# MDR32F8 register map
Vendor: Milandr; File version: 1.0
CPU: CM4 r1p1, little endian, no MPU, no FPU, 3 interrupt priority bits
Registers are 32-bit, read-write, reset 0x0 unless marked. A register's access mark holds for its fields unless they carry their own. Offsets are from the block's base; [hi:lo] are bit positions; {n}, {i} and the like mark numbered series; 'fields as' and 'values as' point back to an identical list.

## ARINC429T — ARINC429 Transive Controller
Base 0x400A0000
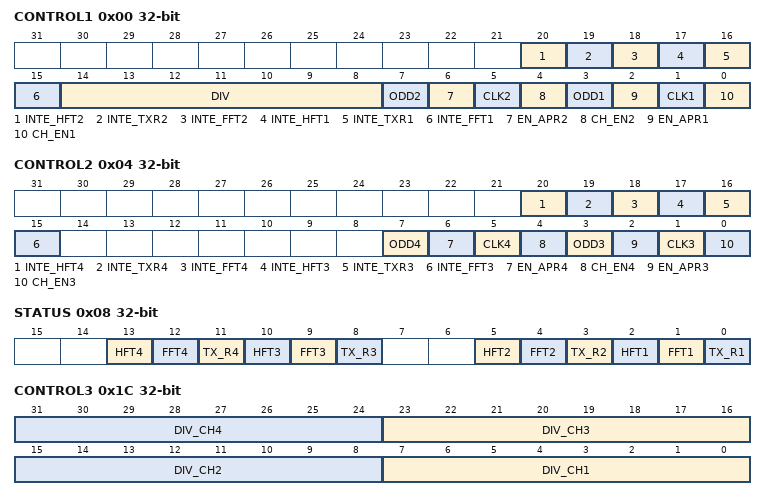
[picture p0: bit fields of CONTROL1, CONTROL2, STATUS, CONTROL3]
0x00 CONTROL1
  [20] INTE_HFT2, [19] INTE_TXR2, [18] INTE_FFT2, [17] INTE_HFT1, [16] INTE_TXR1, [15] INTE_FFT1, [14:8] DIV, [7] ODD2, [6] EN_APR2, [5] CLK2, [4] CH_EN2, [3] ODD1, [2] EN_APR1, [1] CLK1, [0] CH_EN1
0x04 CONTROL2
  [20] INTE_HFT4, [19] INTE_TXR4, [18] INTE_FFT4, [17] INTE_HFT3, [16] INTE_TXR3, [15] INTE_FFT3, [7] ODD4, [6] EN_APR4, [5] CLK4, [4] CH_EN4, [3] ODD3, [2] EN_APR3, [1] CLK3, [0] CH_EN3
0x08 STATUS
  [13] HFT4, [12] FFT4, [11] TX_R4, [10] HFT3, [9] FFT3, [8] TX_R3, [5] HFT2, [4] FFT2, [3] TX_R2, [2] HFT1, [1] FFT1, [0] TX_R1
{0x8+4i} DATA{i}_T wo (i=1..4)
0x1C CONTROL3
  [8n-1:8n-8] DIV_CH{n} (n=1..4)
0x20 CONTROL4
  [3:0] ENSYNC

## MDR_MILDAT_15530 — MIL_DATA
Base 0x400A6000
Same registers: MDR_MILDAT_15531 0x400A8000

## MDR_MIL_STD_15530 — MIL_STD_1553 interfase controller registers
Base 0x400A7000
Same registers: MDR_MIL_STD_15531 0x400A9000
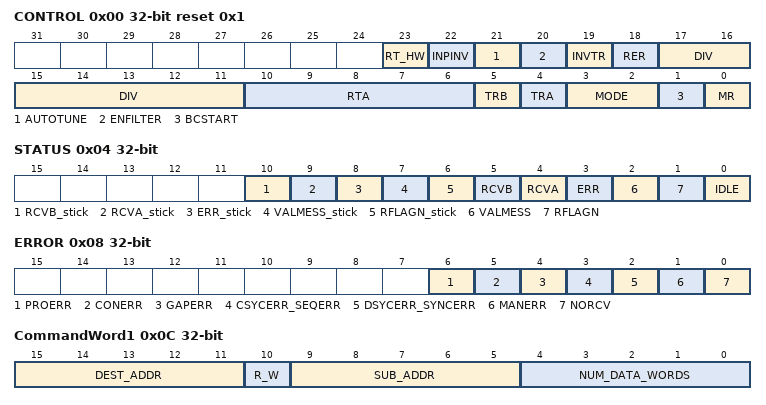
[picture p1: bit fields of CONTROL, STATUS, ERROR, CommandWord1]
0x00 CONTROL reset 0x1 — MIL_STD_1553 Register control
  [23] RT_HW, [22] INPINV, [21] AUTOTUNE, [20] ENFILTER, [19] INVTR, [18] RER, [17:11] DIV, [10:6] RTA, [5] TRB, [4] TRA, [3:2] MODE, [1] BCSTART, [0] MR
0x04 STATUS ro — MIL_STD_1553 Register status
  [10] RCVB_stick, [9] RCVA_stick, [8] ERR_stick, [7] VALMESS_stick, [6] RFLAGN_stick, [5] RCVB, [4] RCVA, [3] ERR, [2] VALMESS, [1] RFLAGN, [0] IDLE
0x08 ERROR ro — MIL_STD_1553 Register error
  [6] PROERR, [5] CONERR, [4] GAPERR, [3] CSYCERR_SEQERR, [2] DSYCERR_SYNCERR, [1] MANERR, [0] NORCV
0x0C CommandWord1 — MIL_STD_1553 Register Command Word 1
  [15:11] DEST_ADDR, [10] R_W, [9:5] SUB_ADDR, [4:0] NUM_DATA_WORDS
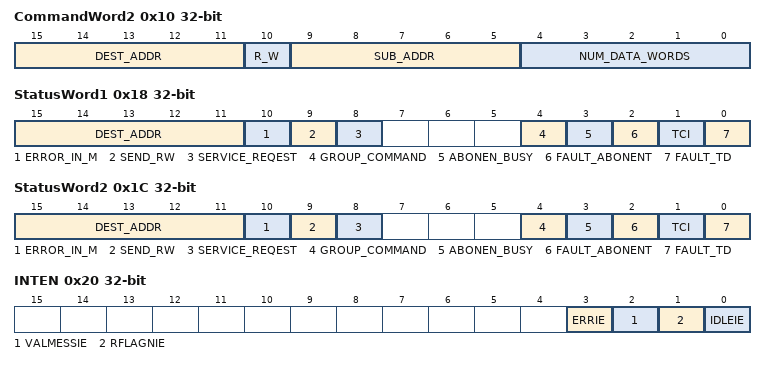
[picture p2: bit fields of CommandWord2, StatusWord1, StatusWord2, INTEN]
0x10 CommandWord2 — MIL_STD_1553 Register Command Word 2
  [15:11] DEST_ADDR, [10] R_W, [9:5] SUB_ADDR, [4:0] NUM_DATA_WORDS
0x14 MODE_DATA — MIL_STD_1553 Register Mode Data
  [15:0] MODE_DATA
0x18 StatusWord1 — MIL_STD_1553 Register Status Word 1
  [15:11] DEST_ADDR, [10] ERROR_IN_M, [9] SEND_RW, [8] SERVICE_REQEST, [4] GROUP_COMMAND, [3] ABONEN_BUSY, [2] FAULT_ABONENT, [1] TCI, [0] FAULT_TD
0x1C StatusWord2 — MIL_STD_1553 Register Status Word 2
  fields as StatusWord1
0x20 INTEN — MIL_STD_1553
  [3] ERRIE, [2] VALMESSIE, [1] RFLAGNIE, [0] IDLEIE
0x24 MSG ro — MIL_STD_1553
  [13:0] MESSAGE_CODE

## ADC0 — ADC
Base 0x400AA000
Same registers: ADC1 0x400AB000
0x00 KEY — Key lock Register
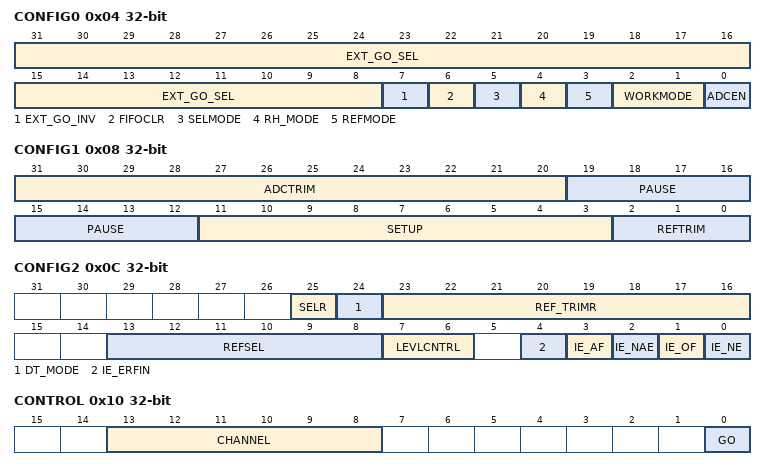
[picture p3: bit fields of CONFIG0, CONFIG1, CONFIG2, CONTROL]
0x04 CONFIG0 — ADC Configuration0 Register
  [31:8] EXT_GO_SEL, [7] EXT_GO_INV, [6] FIFOCLR, [5] SELMODE, [4] RH_MODE, [3] REFMODE, [2:1] WORKMODE, [0] ADCEN
0x08 CONFIG1 — ADC Configuration1 Register
  [31:20] ADCTRIM, [19:12] PAUSE, [11:3] SETUP, [2:0] REFTRIM
0x0C CONFIG2 — ADC Configuration Register
  [25] SELR, [24] DT_MODE, [23:16] REF_TRIMR, [13:8] REFSEL, [7:6] LEVLCNTRL, [4] IE_ERFIN, [3] IE_AF, [2] IE_NAE, [1] IE_OF, [0] IE_NE
0x10 CONTROL — ADC Control Register
  [13:8] CHANNEL, [0] GO
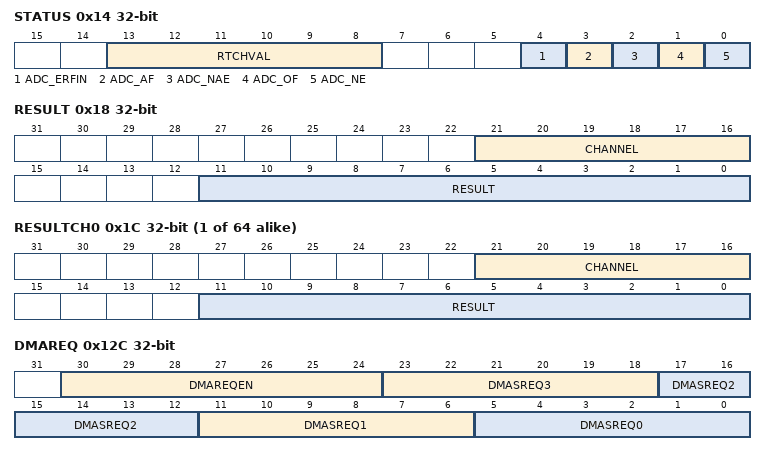
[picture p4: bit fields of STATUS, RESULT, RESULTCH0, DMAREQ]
0x14 STATUS ro — ADC Status Register
  [13:8] RTCHVAL, [4] ADC_ERFIN, [3] ADC_AF, [2] ADC_NAE, [1] ADC_OF, [0] ADC_NE
0x18 RESULT ro — ADC Result Register
  [21:16] CHANNEL, [11:0] RESULT
{0x1C+4i} RESULTCH{i} ro (i=0..63) — ADC Result Register
  [21:16] CHANNEL, [11:0] RESULT
0x11C MAX_LEVEL — ADC MAC Level Register
  [11:0] MAX_LEVEL
0x120 MIN_LEVEL — ADC MIN Level Register
  [11:0] MIN_LEVEL
0x124 CHSEL0 (reset mask 0xFFFFFFF) — Selec Channel Register
  [31:0] CHSEL
0x128 CHSEL1 (reset mask 0xFFFFFFF) — Selec Channel Register
  [31:0] CHSEL
0x12C DMAREQ — DMA Request Register
  [30:24] DMAREQEN, [6n+5:6n] DMASREQ{n} (n=0..3)
0x130 STATRCH0 ro — ADC STAT Register
  [30:0] STRCH
0x134 STATRCH1 ro — ADC STAT Register
  [30:0] STRCH
0x138 FIFOEN0 — ADC FIFO write Enable
  [31:0] FIFOEN
0x13C FIFOEN1 — ADC FIFO write Enable
  [31:0] FIFOEN
